# SC32F10T_10G register map
File version: 1.0
CPU: CM0+ r0p1, little endian, MPU, no FPU, 4 interrupt priority bits
Registers are 32-bit, access not given, reset 0x0 unless marked. A register's access mark holds for its fields unless they carry their own. Offsets are from the block's base; [hi:lo] are bit positions; {n}, {i} and the like mark numbered series; 'fields as' and 'values as' point back to an identical list.

## RCCAHB — RCCAHB peripheral (RCCAHB_TypeDef)
Base 0x40003000
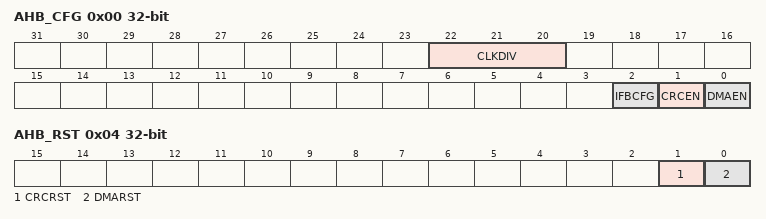
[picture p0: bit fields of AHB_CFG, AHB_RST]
0x00 AHB_CFG rw — APB2 Config register
  [22:20] CLKDIV, [2] IFBCFG, [1] CRCEN, [0] DMAEN
0x04 AHB_RST rw — APB2 Reset register
  [1] CRCRST, [0] DMARST

## RCCAPB0 — RCCAPB0 peripheral (RCCAPB0_TypeDef)
Base 0x40020000
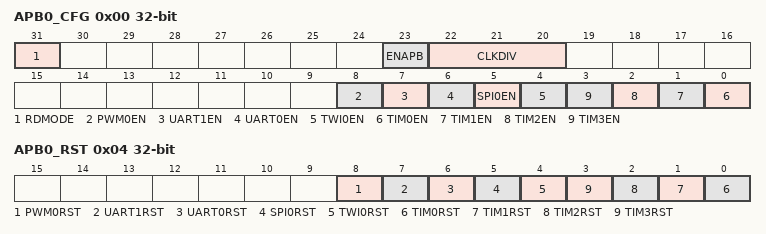
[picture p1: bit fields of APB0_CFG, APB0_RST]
0x00 APB0_CFG rw — APB0 Config register
  [31] RDMODE, [23] ENAPB, [22:20] CLKDIV, [8] PWM0EN, [7] UART1EN, [6] UART0EN, [5] SPI0EN, [4] TWI0EN, [n] TIM{n}EN (n=0..3)
0x04 APB0_RST rw — APB0 Reset register
  [8] PWM0RST, [7] UART1RST, [6] UART0RST, [5] SPI0RST, [4] TWI0RST, [n] TIM{n}RST (n=0..3)

## RCCAPB1 — RCCAPB1 peripheral (RCCAPB1_TypeDef)
Base 0x40021000
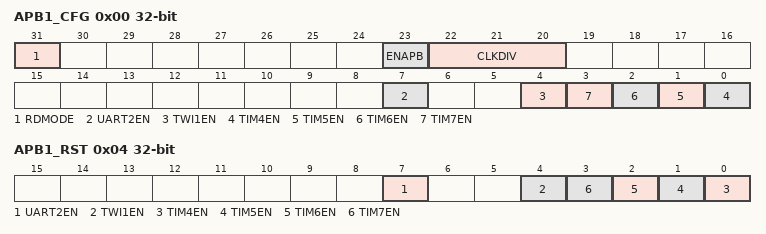
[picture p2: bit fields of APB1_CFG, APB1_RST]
0x00 APB1_CFG rw — APB1 Config register
  [31] RDMODE, [23] ENAPB, [22:20] CLKDIV, [7] UART2EN, [4] TWI1EN, [n-4] TIM{n}EN (n=4..7)
0x04 APB1_RST rw — APB1 Reset register
  [7] UART2EN, [4] TWI1EN, [n-4] TIM{n}EN (n=4..7)

## RCCAPB2 — RCCAPB2 peripheral (RCCAPB2_TypeDef)
Base 0x40022000
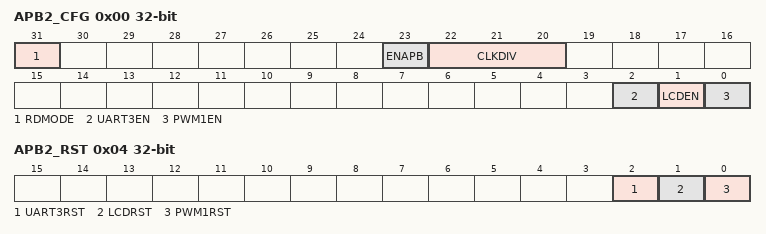
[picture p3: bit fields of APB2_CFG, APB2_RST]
0x00 APB2_CFG rw — APB2 Config register
  [31] RDMODE, [23] ENAPB, [22:20] CLKDIV, [2] UART3EN, [1] LCDEN, [0] PWM1EN
0x04 APB2_RST rw — APB2 Reset register
  [2] UART3RST, [1] LCDRST, [0] PWM1RST

## UART0
Base 0x40020020
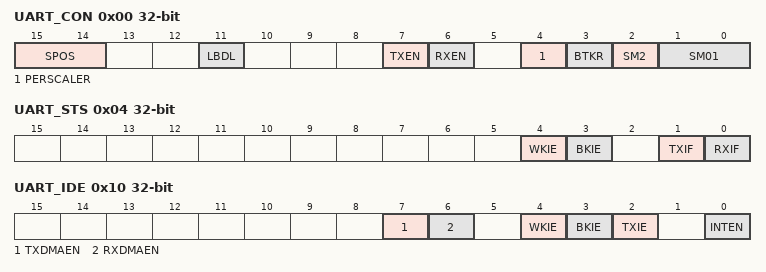
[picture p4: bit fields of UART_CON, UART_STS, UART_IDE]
0x00 UART_CON rw — UART控制寄存器
  [15:14] SPOS — 此bit位，仅在UARTn_CON，n=2的情况下有效：UART2信号口映射控制位@UART2_CON信号SPOS值RX2TX2SPOS[1:0]=00PB0PA15SPOS[1:0]=01PA11PA10
  [11] LBDL
  [7] TXEN — UART发送允许控制位0：不允许发送数据，TXD信号不再影响所在管脚的状态。此时若用户程序限制发送功能，仅用到了接收，那么与TX脚复用的其它功能将不受影响1：允许发送数据，TXD所在管脚切换为TXD信号口模式
  [6] RXEN — UART接收允许控制位0：不允许接收数据1：允许接收数据
  [4] PERSCALER — 波特率倍率设置位该位在UART的不同模式下有不同定义：当SM0~1 = 01（UART模式1）或SM0~1 = 11（UART模式3）：0: 串行端口在系统时钟的1分频下运行1: 串行端口在系统时钟的16分频下运行当SM0~1 = 00（UART模式0）波特率倍率设置位：0：串行端口在系统时钟的12分频下运行1：串行端口在系统时钟的4分频下运行
  [3] BTKR
  [2] SM2 — RB8置位中断允许位该位仅在模式3有效0：每收到一个完整的数据帧就置位RI产生中断请求；1：收到一个完整的数据帧时，只有当RB8=1时才会置位RI产生中断请求
  [1:0] SM01
0x04 UART_STS rw — UART标志位寄存器
  [4] WKIE — UART唤醒标志位UART从STOP模式唤醒后，该位由硬件置1，如果此时WKIE = 1，将产生中断。该位由软件写1清0。
  [3] BKIE
  [1] TXIF — 发送中断标志位数据发送完成该位由硬件置1，如果此时TXIE = 1，将产生中断。该位由软件写1清0。注意：在DMA模式下，DMA写入发送缓存后，该位由DMA模块清0，此时用户无需通过软件清0。
  [0] RXIF — 接收中断标志位数据接收完成该位由硬件置1，如果此时RXIE = 1，将产生中断。该位由软件写1清0。注意：在DMA模式下，DMA读取接收缓存后，该位由DMA模块清0，此时用户无需通过软件清0。
0x08 UART_BAUD — UART波特率寄存器
0x0C UART_DATA — UART数据寄存器
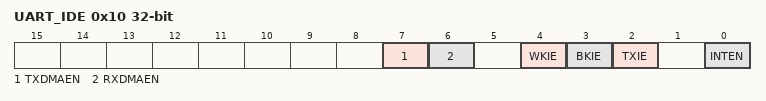
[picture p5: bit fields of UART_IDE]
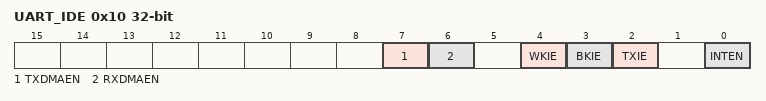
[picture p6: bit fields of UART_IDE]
0x10 UART_IDE rw — 通信口DMA控制寄存器
  [7] TXDMAEN — DMA发送通道使能位0：禁用DMA发送功能1：使能DMA发送功能该位使能后，TXIF置起可触发DMA通道发送请求注意：UART0和UART1可产生DMA请求UART2和UART3不能产生DMA请求
  [6] RXDMAEN — DMA接收通道使能位0：禁用DMA接收功能1：使能DMA接收功能该位使能后，RXIF置起可触发DMA通道接收请求注意：UART0和UART1可产生DMA请求UART2和UART3不能产生DMA请求
  [4] WKIE — UART唤醒中断使能位0：WKIF置起时，不允许产生中断1：WKIF置起时，产生中断
  [3] BKIE
  [2] TXIE — UART发送中断使能位0：TXIF置起时，不允许产生中断1：TXIF置起时，产生中断
  [0] INTEN — 中断请求 CPU的使能控制位0：禁止中断请求1：使能中断请求

## UART1
Base 0x40020080
Registers as UART0; these are added or differ:
0x10 UART_IDE rw — 通信口DMA控制寄存器
  fields as UART0.UART_IDE

## UART3
Base 0x40022020
Registers as UART0; these are added or differ:
0x10 UART_IDE rw — 通信口DMA控制寄存器
  fields as UART0.UART_IDE

## UART2
Base 0x40021020
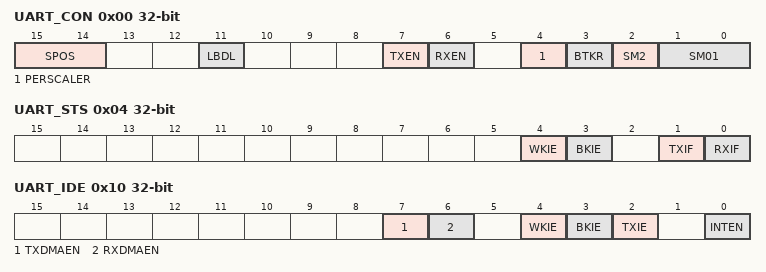
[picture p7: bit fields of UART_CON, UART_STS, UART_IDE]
0x00 UART_CON rw — UART控制寄存器
  [15:14] SPOS — 此bit位，仅在UARTn_CON，n=2的情况下有效：UART2信号口映射控制位@UART2_CON信号SPOS值RX2TX2SPOS[1:0]=00PB0PA15SPOS[1:0]=01PA11PA10
  [11] LBDL
  [7] TXEN — UART发送允许控制位0：不允许发送数据，TXD信号不再影响所在管脚的状态。此时若用户程序限制发送功能，仅用到了接收，那么与TX脚复用的其它功能将不受影响1：允许发送数据，TXD所在管脚切换为TXD信号口模式
  [6] RXEN — UART接收允许控制位0：不允许接收数据1：允许接收数据
  [4] PERSCALER — 波特率倍率设置位该位在UART的不同模式下有不同定义：当SM0~1 = 01（UART模式1）或SM0~1 = 11（UART模式3）：0: 串行端口在系统时钟的1分频下运行1: 串行端口在系统时钟的16分频下运行当SM0~1 = 00（UART模式0）波特率倍率设置位：0：串行端口在系统时钟的12分频下运行1：串行端口在系统时钟的4分频下运行
  [3] BTKR
  [2] SM2 — RB8置位中断允许位该位仅在模式3有效0：每收到一个完整的数据帧就置位RI产生中断请求；1：收到一个完整的数据帧时，只有当RB8=1时才会置位RI产生中断请求
  [1:0] SM01
0x04 UART_STS rw — UART标志位寄存器
  [4] WKIE — UART唤醒标志位UART从STOP模式唤醒后，该位由硬件置1，如果此时WKIE = 1，将产生中断。该位由软件写1清0。
  [3] BKIE
  [1] TXIF — 发送中断标志位数据发送完成该位由硬件置1，如果此时TXIE = 1，将产生中断。该位由软件写1清0。注意：在DMA模式下，DMA写入发送缓存后，该位由DMA模块清0，此时用户无需通过软件清0。
  [0] RXIF — 接收中断标志位数据接收完成该位由硬件置1，如果此时RXIE = 1，将产生中断。该位由软件写1清0。注意：在DMA模式下，DMA读取接收缓存后，该位由DMA模块清0，此时用户无需通过软件清0。
0x08 UART_BAUD — UART波特率寄存器
0x0C UART_DATA — UART数据寄存器
0x10 UART_IDE rw — 通信口DMA控制寄存器
  [7] TXDMAEN — DMA发送通道使能位0：禁用DMA发送功能1：使能DMA发送功能该位使能后，TXIF置起可触发DMA通道发送请求注意：UART0和UART1可产生DMA请求UART2和UART3不能产生DMA请求
  [6] RXDMAEN — DMA接收通道使能位0：禁用DMA接收功能1：使能DMA接收功能该位使能后，RXIF置起可触发DMA通道接收请求注意：UART0和UART1可产生DMA请求UART2和UART3不能产生DMA请求
  [4] WKIE — UART唤醒中断使能位0：WKIF置起时，不允许产生中断1：WKIF置起时，产生中断
  [3] BKIE
  [2] TXIE — UART发送中断使能位0：TXIF置起时，不允许产生中断1：TXIF置起时，产生中断
  [0] INTEN — 中断请求 CPU的使能控制位0：禁止中断请求1：使能中断请求
